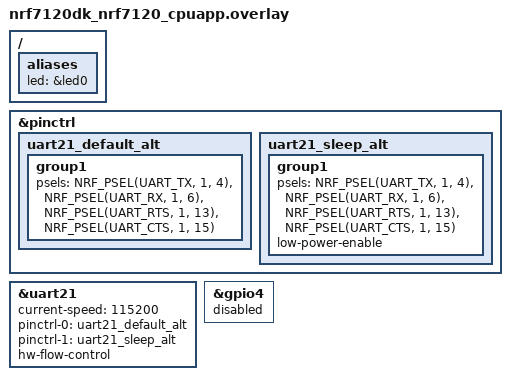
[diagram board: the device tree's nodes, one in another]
/*
 * Copyright (c) 2026 Nordic Semiconductor ASA
 *
 * SPDX-License-Identifier: LicenseRef-Nordic-5-Clause
 */

/*
 * Required loopbacks
 * P1.04 - P1.06
 * P1.13 - P1.15
 */

/ {
	aliases {
		led = &led0;
	};
};

&pinctrl {
	uart21_default_alt: uart21_default_alt {
		group1 {
			psels = <NRF_PSEL(UART_TX, 1, 4)>,
				<NRF_PSEL(UART_RX, 1, 6)>,
				<NRF_PSEL(UART_RTS, 1, 13)>,
				<NRF_PSEL(UART_CTS, 1, 15)>;
		};
	};

	uart21_sleep_alt: uart21_sleep_alt {
		group1 {
			psels = <NRF_PSEL(UART_TX, 1, 4)>,
				<NRF_PSEL(UART_RX, 1, 6)>,
				<NRF_PSEL(UART_RTS, 1, 13)>,
				<NRF_PSEL(UART_CTS, 1, 15)>;
			low-power-enable;
		};
	};
};

dut: &uart21 {
	status = "okay";
	current-speed = <115200>;
	pinctrl-0 = <&uart21_default_alt>;
	pinctrl-1 = <&uart21_sleep_alt>;
	pinctrl-names = "default", "sleep";
	hw-flow-control;
};

&gpio4 {
	status = "disabled";
};
